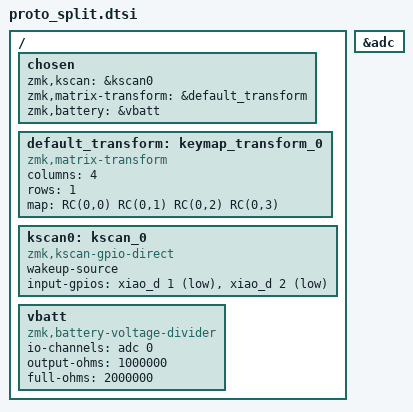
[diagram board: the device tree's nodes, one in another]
/*
 * Task C3: BLE 分割だけを切り出して確かめる治具。左右で共通の土台。
 *
 * 本番シールドは 74HC595 と 61 キーが前提なので、分割の検証には重すぎる。
 * ここではキースキャンを最も単純な直結（ダイオードもシフトレジスタも無し）に
 * して、**左右が無線でつながるかどうかだけ**を見る。
 *
 * 左 2 キー（a b）＋ 右 2 キー（c d）。配線は Task C1 とほぼ同じで、
 * スイッチの片側を D1・D2 へ、反対側を GND へ落とすだけ。
 *
 * BLE は当然 有効 のまま。ここで無効にしたら検証にならない。
 * （C1・C2 では変数を減らすために切っていたが、このタスクでは主役）
 *
 * **D0 はキーに使わない（2026-08-08）。** Task C5（電池残量）で D0 = AIN0 を
 * ADC に使うため。この治具は C4・C5 でも先に使うので、キーを D1・D2 へ寄せて
 * D0 を空けた。ADC が使えるのは D0..D5 だけで、本番シールドも同じ割り当て。
 */
#include <dt-bindings/zmk/matrix_transform.h>

/ {
	chosen {
		zmk,kscan = &kscan0;
		zmk,matrix-transform = &default_transform;
		zmk,battery = &vbatt;
	};

	/*
	 * 左右で 1 つの transform を共有し、右半分に col-offset を足す。
	 * ZMK の分割の標準的な書き方（本番シールドと同じ考え方）。
	 *
	 * 直結スキャンは 1 行 × N 列として扱われる。
	 *   左が列 0・1、右が列 2・3。
	 */
	default_transform: keymap_transform_0 {
		compatible = "zmk,matrix-transform";
		columns = <4>;
		rows = <1>;
		map = <
			RC(0,0) RC(0,1)   RC(0,2) RC(0,3)
		>;
	};

	kscan0: kscan_0 {
		compatible = "zmk,kscan-gpio-direct";
		wakeup-source;
		input-gpios
			= <&xiao_d 1 (GPIO_ACTIVE_LOW | GPIO_PULL_UP)>
			, <&xiao_d 2 (GPIO_ACTIVE_LOW | GPIO_PULL_UP)>
			;
	};

	/* Task C5: 電池電圧の測定。本番シールド（hhkb_split.dtsi）と同じ値。
	 * 分圧 1MΩ + 1MΩ を D0 (P0.02 = AIN0) で読む。測定点はショットキーの
	 * 手前（電池側）なので、USB 接続中も電池そのものの電圧が読める。
	 *
	 * **2026-08-09 に実測で確かめた。**抵抗は R1 976kΩ / R2 987kΩ で
	 * どちらも ±5% 以内。ADC は真値 1508mV を 1512〜1515mV と読んだ（+0.3%）。
	 * **設定を実測値へ入れ直す必要は無い。**
	 *
	 * 確かめ方は素直ではなかった。ZMK の残量 % はリチウムイオンの曲線で
	 * 計算され、**3450mV 以下は一律 0%**（battery_common.c）。乾電池 2 本は
	 * 常に 0% になるので、**ADC が正しく読んでも壊れていても同じ 0%** で、
	 * 区別できない。そこで full-ohms を一時的に 2.5 倍にして 0% に潰れない
	 * 領域へ持ち上げ、表示された % から ADC の読みを逆算した（分解能 3mV）。
	 * 手順は docs/hardware/task-c4-c5-power.md の §8。
	 */
	vbatt: vbatt {
		compatible = "zmk,battery-voltage-divider";
		io-channels = <&adc 0>;
		output-ohms = <1000000>;
		full-ohms = <2000000>;
	};

};

&adc {
	status = "okay";
};
